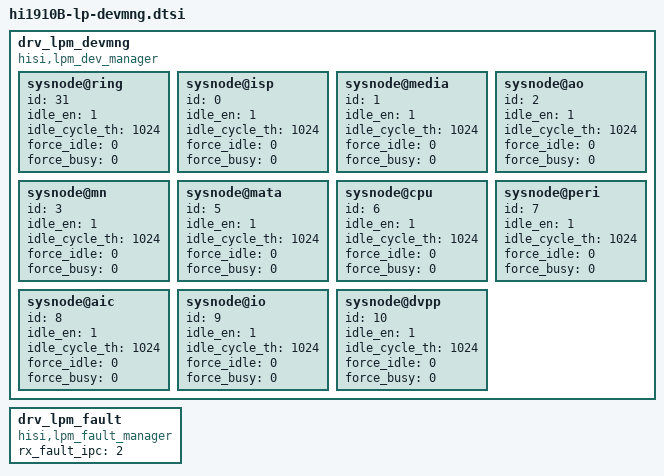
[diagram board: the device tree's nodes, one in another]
    /*
     * lpm devmng property desc:
     *
     * "id", subsystem id which support idle
     * "idle_en", whether to enable idle, "1" means enable idle, "0" means disable idle
     * "idle_cycle_th", idle threshold, which requires the idle indication to be output after each cycle of continuous clk_cycle is idle
     *                  range: 1~65535
     * "force_idle", force module idle mask, each submodule occupies 1 bit,
     *               "1" means force module idle, "0" means not force module idle.
     * "force_busy", force module busy mask, each submodule occupies 1 bit,
     *               "1" forces the module to be non-idle, "0" means not to force the module to be non-idle
     */
    drv_lpm_devmng {
        compatible = "hisi,lpm_dev_manager";

        sysnode@ring {
            id = <31>;
            idle_en = <1>;
            idle_cycle_th = <1024>;
            force_idle = <0>;
            force_busy = <0>;
        };

        sysnode@isp {
            id = <0>;
            idle_en = <1>;
            idle_cycle_th = <1024>;
            force_idle = <0>;
            force_busy = <0>;
        };

        sysnode@media {
            id = <1>;
            idle_en = <1>;
            idle_cycle_th = <1024>;
            force_idle = <0>;
            force_busy = <0>;
        };

        sysnode@ao {
            id = <2>;
            idle_en = <1>;
            idle_cycle_th = <1024>;
            force_idle = <0>;
            force_busy = <0>;
        };

        sysnode@mn {
            id = <3>;
            idle_en = <1>;
            idle_cycle_th = <1024>;
            force_idle = <0>;
            force_busy = <0>;
        };

        sysnode@mata {
            id = <5>;
            idle_en = <1>;
            idle_cycle_th = <1024>;
            force_idle = <0>;
            force_busy = <0>;
        };

        sysnode@cpu {
            id = <6>;
            idle_en = <1>;
            idle_cycle_th = <1024>;
            force_idle = <0>;
            force_busy = <0>;
        };

        sysnode@peri {
            id = <7>;
            idle_en = <1>;
            idle_cycle_th = <1024>;
            force_idle = <0>;
            force_busy = <0>;
        };

        sysnode@aic {
            id = <8>;
            idle_en = <1>;
            idle_cycle_th = <1024>;
            force_idle = <0>;
            force_busy = <0>;
        };

        sysnode@io {
            id = <9>;
            idle_en = <1>;
            idle_cycle_th = <1024>;
            force_idle = <0>;
            force_busy = <0>;
        };

        sysnode@dvpp {
            id = <10>;
            idle_en = <1>;
            idle_cycle_th = <1024>;
            force_idle = <0>;
            force_busy = <0>;
        };
    };

    drv_lpm_fault {
        compatible = "hisi,lpm_fault_manager";
        rx_fault_ipc = <2>;
    };

